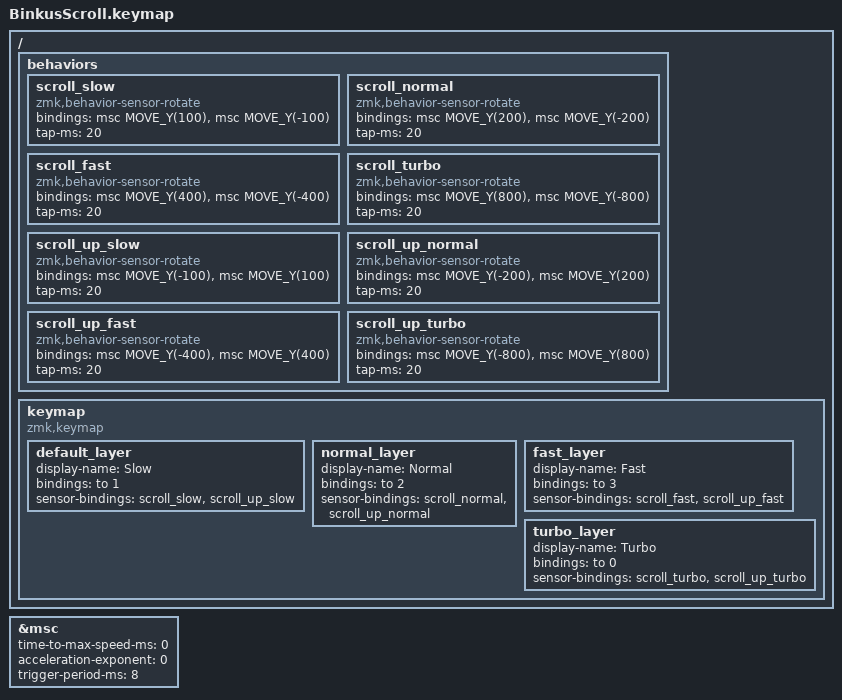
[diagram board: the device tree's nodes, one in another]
#include <behaviors.dtsi>
#include <dt-bindings/zmk/keys.h>

#define ZMK_POINTING_DEFAULT_SCRL_VAL 100

#include <dt-bindings/zmk/pointing.h>
#include <zephyr/dt-bindings/input/input-event-codes.h>

&msc {
    time-to-max-speed-ms = <0>;   /* no ramp */
    acceleration-exponent = <0>;  /* linear */
    trigger-period-ms = <8>;
};

/ {
    behaviors {
        /* Scroll DOWN behaviors (negative values) */
        scroll_slow: scroll_slow {
            compatible = "zmk,behavior-sensor-rotate";
            #sensor-binding-cells = <0>;
            bindings = <&msc MOVE_Y(100)>, <&msc MOVE_Y(-100)>;
            tap-ms = <20>;
        };

        scroll_normal: scroll_normal {
            compatible = "zmk,behavior-sensor-rotate";
            #sensor-binding-cells = <0>;
            bindings = <&msc MOVE_Y(200)>, <&msc MOVE_Y(-200)>;
            tap-ms = <20>;
        };

        scroll_fast: scroll_fast {
            compatible = "zmk,behavior-sensor-rotate";
            #sensor-binding-cells = <0>;
            bindings = <&msc MOVE_Y(400)>, <&msc MOVE_Y(-400)>;
            tap-ms = <20>;
        };

        scroll_turbo: scroll_turbo {
            compatible = "zmk,behavior-sensor-rotate";
            #sensor-binding-cells = <0>;
            bindings = <&msc MOVE_Y(800)>, <&msc MOVE_Y(-800)>;
            tap-ms = <20>;
        };

        /* Scroll UP behaviors (positive values) */
        scroll_up_slow: scroll_up_slow {
            compatible = "zmk,behavior-sensor-rotate";
            #sensor-binding-cells = <0>;
            bindings = <&msc MOVE_Y(-100)>, <&msc MOVE_Y(100)>;
            tap-ms = <20>;
        };

        scroll_up_normal: scroll_up_normal {
            compatible = "zmk,behavior-sensor-rotate";
            #sensor-binding-cells = <0>;
            bindings = <&msc MOVE_Y(-200)>, <&msc MOVE_Y(200)>;
            tap-ms = <20>;
        };

        scroll_up_fast: scroll_up_fast {
            compatible = "zmk,behavior-sensor-rotate";
            #sensor-binding-cells = <0>;
            bindings = <&msc MOVE_Y(-400)>, <&msc MOVE_Y(400)>;
            tap-ms = <20>;
        };

        scroll_up_turbo: scroll_up_turbo {
            compatible = "zmk,behavior-sensor-rotate";
            #sensor-binding-cells = <0>;
            bindings = <&msc MOVE_Y(-800)>, <&msc MOVE_Y(800)>;
            tap-ms = <20>;
        };
    };

    keymap {
        compatible = "zmk,keymap";

        /* Layer 0 → Layer 1 */
        default_layer {
            display-name = "Slow";
            bindings = <&to 1>;
            sensor-bindings = <&scroll_slow &scroll_up_slow>;
        };

        /* Layer 1 → Layer 2 */
        normal_layer {
            display-name = "Normal";
            bindings = <&to 2>;
            sensor-bindings = <&scroll_normal &scroll_up_normal>;
        };

        /* Layer 2 → Layer 3 */
        fast_layer {
            display-name = "Fast";
            bindings = <&to 3>;
            sensor-bindings = <&scroll_fast &scroll_up_fast>;
        };

        /* Layer 3 → Layer 0 */
        turbo_layer {
            display-name = "Turbo";
            bindings = <&to 0>;
            sensor-bindings = <&scroll_turbo &scroll_up_turbo>;
        };
    };
};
